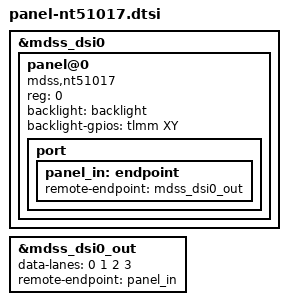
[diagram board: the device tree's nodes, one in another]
&mdss_dsi0 {
	panel@0 {
		compatible = "mdss,nt51017";
		reg = <0>;

		backlight = <&backlight>;
		backlight-gpios = <&tlmm XY GPIO_ACTIVE_HIGH>;

		port {
			panel_in: endpoint {
				remote-endpoint = <&mdss_dsi0_out>;
			};
		};
	};
};

&mdss_dsi0_out {
	data-lanes = <0 1 2 3>;
	remote-endpoint = <&panel_in>;
};
